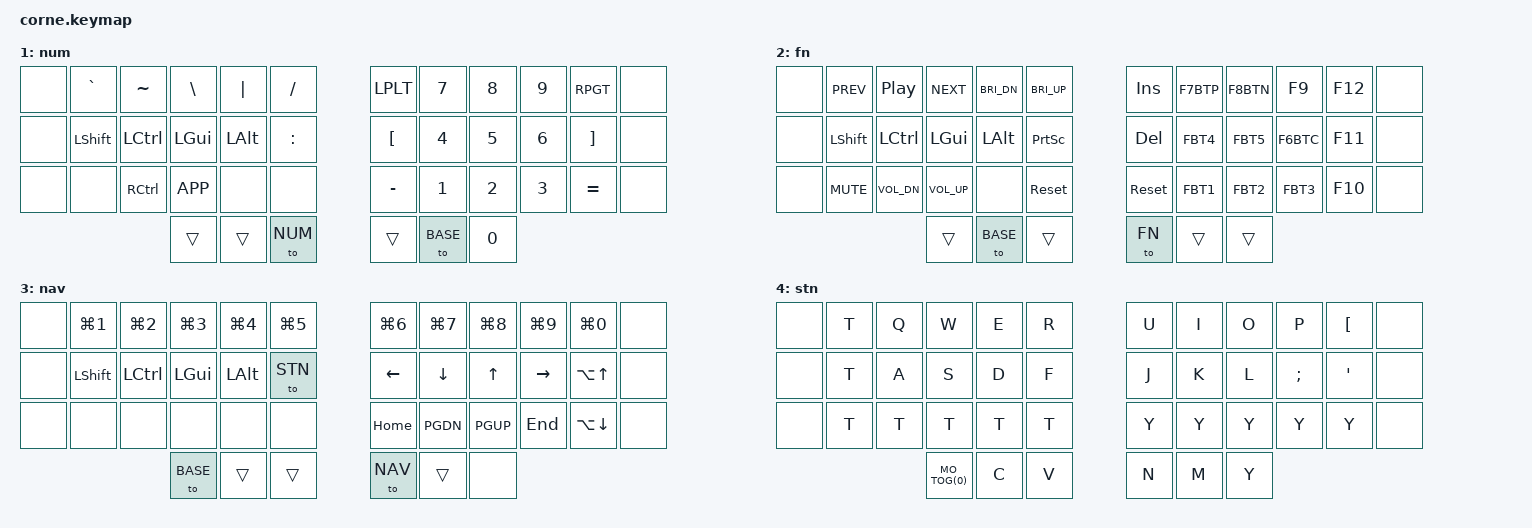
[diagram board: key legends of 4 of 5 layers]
#include <behaviors.dtsi>
#include <dt-bindings/zmk/keys.h>
#include <dt-bindings/zmk/bt.h>

/*────┬─────┬─────┬─────┬────L0:BASE──┬─────┬─────┬─────┬─────╮
│ ' " │ , < │ . > │ p P │ y Y │ │ f F │ g G │ c C │ r R │ l L │
│     │     │     │     │     │ │     │     │     │     │     │
├─────┼─────┼─────┼─────┼─────┤ ├─────┼─────┼─────┼─────┼─────┤
│ a A │ o O │ e E │ u U │ i I │ │ d D │ h H │ t T │ n N │ s S │
│ SHF │ CTL │ GUI │ ALT │     │ │     │ ALT │ GUI │ CTL │ SHF │
├─────┼─────┼─────┼─────┼─────┤ ├─────┼─────┼─────┼─────┼─────┤
│ ; : │ q Q │ j J │ k K │ x X │ │ b B │ m M │ w W │ v V │ z Z │
│     │     │     │     │     │ │     │     │     │     │     │
╰─────┴─────┼─────┼─────┼─────┤ ├─────┼─────┼─────┼─────┴─────╯
            │ ESC │BSPC │ TAB │ │ RET │SPACE│ / ? │
            │ NAV │ FN  │     │ │     │ NUM │     │
            ╰─────┴─────┴─────╯ ╰─────┴─────┴─────╯
╭─────┬─────┬─────┬─────┬────L1:NUM───┬─────┬─────┬─────┬─────╮
│  `  │  ~  │  \  │  |  │  /  │ │ ( < │ 7 & │ 8 * │  9  │ ) > │
│     │     │     │     │     │ │     │     │     │     │     │
├─────┼─────┼─────┼─────┼─────┤ ├─────┼─────┼─────┼─────┼─────┤
│ SHF │ CTL │ GUI │ ALT │  :  │ │ [ { │ 4 $ │ 5 % │ 6 ^ │ ] } │
│     │     │     │     │     │ │     │     │     │     │     │
├─────┼─────┼─────┼─────┼─────┤ ├─────┼─────┼─────┼─────┼─────┤
│ ... │RCTL │MENU │ ... │ ... │ │ - _ │ 1 ! │ 2 @ │ 3 # │ = + │
│     │     │     │     │     │ │     │     │     │     │     │
╰─────┴─────┼─────┼─────┼─────┤ ├─────┼─────┼─────┼─────┴─────╯
            │     │     │ NUM │ │     │BASE │  0  │
            │     │     │     │ │     │     │     │
            ╰─────┴─────┴─────╯ ╰─────┴─────┴─────╯
╭─────┬─────┬─────┬─────┬────L2:FN────┬─────┬─────┬─────┬─────╮
│PREV │ PP  │NEXT │BRIDN│BRIUP│ │ INS │F7 BP│F8 BN│F9   │ F12 │
│     │     │     │     │     │ │     │     │     │     │     │
├─────┼─────┼─────┼─────┼─────┤ ├─────┼─────┼─────┼─────┼─────┤
│ SHF │ CTL │ GUI │ ALT │PSCRN│ │ DEL │F4 B4│F5 B5│F6 BC│ F11 │
│     │     │     │     │     │ │     │     │     │     │     │
├─────┼─────┼─────┼─────┼─────┤ ├─────┼─────┼─────┼─────┼─────┤
│MUTE │ VDN │ VUP │ ... │RESET│ │RESET│F1 B1│F2 B2│F3 B3│ F10 │
│     │     │     │     │     │ │     │     │     │     │     │
╰─────┴─────┼─────┼─────┼─────┤ ├─────┼─────┼─────┼─────┴─────╯
            │     │BASE │     │ │ FN  │     │     │ ↑ GUI for
            │     │     │     │ │     │     │     │ B* (BT)
            ╰─────┴─────┴─────╯ ╰─────┴─────┴─────╯
╭─────┬─────┬─────┬─────┬────L3:NAV───┬─────┬─────┬─────┬─────╮
│LG(1)│LG(2)│LG(3)│LG(4)│LG(5)│ │LG(6)│LG(7)│LG(8)│LG(9)│LG(0)│
│     │     │     │     │     │ │     │     │     │     │     │
├─────┼─────┼─────┼─────┼─────┤ ├─────┼─────┼─────┼─────┼─────┤
│ SHF │ CTL │ GUI │ ALT │ STN │ │  ←  │  ↓  │  ↑  │  →  │LA(↑)│
│     │     │     │     │     │ │     │     │     │     │     │
├─────┼─────┼─────┼─────┼─────┤ ├─────┼─────┼─────┼─────┼─────┤
│ ... │ ... │ ... │ ... │ ... │ │HOME │ PG↓ │ PG↑ │ END │LA(↓)│
│     │     │     │     │     │ │     │     │     │     │     │
╰─────┴─────┼─────┼─────┼─────┤ ├─────┼─────┼─────┼─────┴─────╯
            │BASE │     │     │ │ NAV │LGTAB│     │
            │     │     │     │ │     │     │     │
            ╰─────┴─────┴─────╯ ╰─────┴─────┴─────╯
╭─────┬─────┬─────┬─────┬────L4:STN───┬─────┬─────┬─────┬─────╮
│  t  │  q  │  w  │  e  │  r  │ │  u  │  i  │  o  │  p  │  [  │
│     │     │     │     │     │ │     │     │     │     │     │
├─────┼─────┼─────┼─────┼─────┤ ├─────┼─────┼─────┼─────┼─────┤
│  t  │  a  │  s  │  d  │  f  │ │  j  │  k  │  l  │  ;  │  '  │
│     │     │     │     │     │ │     │     │     │     │     │
├─────┼─────┼─────┼─────┼─────┤ ├─────┼─────┼─────┼─────┼─────┤
│  t  │  t  │  t  │  t  │  t  │ │  y  │  y  │  y  │  y  │  y  │
│     │     │     │     │     │ │     │     │     │     │     │
╰─────┴─────┼─────┼─────┼─────┤ ├─────┼─────┼─────┼─────┴─────╯
            │ LV0 │  c  │  v  │ │  n  │  m  │  y  │
            │ LV0 │     │     │ │     │     │     │
            ╰─────┴─────┴─────╯ ╰─────┴─────┴────*/

#define NOP &none
#define __ &trans

#define LKEYS  1  2  3  4  5  13 14 15 16 17  25 26 27 28 29  36 37 38
#define RKEYS  6  7  8  9 10  18 19 20 21 22  30 31 32 33 34  39 40 41

#define BASE 0
#define NUM  1
#define FN   2
#define NAV  3
#define STN  4

#define NAV_ESC &ltb   NAV ESC
#define FN_BSPC &ltb   FN BSPC
#define NUM_SPACE &ltb NUM SPACE

// #define NAV_SPACE &ltb NAV SPACE
// #define NAV_BSPC  &ltb NAV BSPC
// #define NUM_TAB   &ltb NUM TAB
// #define FN_TAB    &ltb FN  TAB
// #define NUM_RET   &ltb NUM RET
// #define FN_BSPC   &ltb FN  BSPC

#define VMUTE &kp C_MUTE
#define VOLDN &kp C_VOL_DN
#define VOLUP &kp C_VOL_UP
#define BRIDN &kp C_BRI_DN
#define BRIUP &kp C_BRI_UP
#define PREV  &kp C_PREV
#define PP    &kp C_PP
#define NEXT  &kp C_NEXT

#define MO_TOG(layer) &mo_tog layer layer

#define HL(k1,k2,k3,k4) &hml LSHFT k1  &hml LCTRL k2  &hml LGUI k3  &hml LALT k4
#define HR(k1,k2,k3,k4) &hmr LALT k1  &hmr LGUI k2  &hmr LCTRL k3  &hmr LSHFT k4

/ {
  behaviors {
    mo_tog: behavior_mo_tog {
      compatible = "zmk,behavior-hold-tap";
      #binding-cells = <2>;
      flavor = "hold-preferred";
      tapping-term-ms = <200>;
      bindings = <&mo>, <&tog>;
    };
    ltb: layer_tap_balanced {
      compatible = "zmk,behavior-hold-tap";
      #binding-cells = <2>;
      flavor = "balanced";
      require-prior-idle-ms = <50>;
      tapping-term-ms = <170>;
      quick-tap-ms = <100>;
      bindings = <&mo>, <&kp>;
      display-name = "Layer-Tap";
      hold-trigger-on-release;
    };
    hml: home_row_mod_left {
      compatible = "zmk,behavior-hold-tap";
      #binding-cells = <2>;
      flavor = "balanced";
      require-prior-idle-ms = <50>;
      tapping-term-ms = <170>;
      quick-tap-ms = <100>;
      bindings = <&kp>, <&kp>;
      hold-trigger-key-positions = <RKEYS>;
      hold-trigger-on-release;
    };
    hmr: home_row_mod_right {
      compatible = "zmk,behavior-hold-tap";
      #binding-cells = <2>;
      flavor = "balanced";
      require-prior-idle-ms = <50>;
      tapping-term-ms = <170>;
      quick-tap-ms = <100>;
      bindings = <&kp>, <&kp>;
      hold-trigger-key-positions = <LKEYS>;
      hold-trigger-on-release;
    };
    LPLT: morph_LPAR_LT {
      compatible = "zmk,behavior-mod-morph";
      #binding-cells = <0>;
      bindings = <&kp LPAR>, <&kp LT>;
      mods = <(MOD_LSFT)>;
    };
    RPGT: morph_RPAR_GT {
      compatible = "zmk,behavior-mod-morph";
      #binding-cells = <0>;
      bindings = <&kp RPAR>, <&kp GT>;
      mods = <(MOD_LSFT)>;
    };
    FBT1: morph_F_BT_1 {
      compatible = "zmk,behavior-mod-morph";
      #binding-cells = <0>;
      bindings = <&kp F1>, <&bt BT_SEL 0>;
      mods = <(MOD_LGUI)>;
    };
    FBT2: morph_F_BT_2 {
      compatible = "zmk,behavior-mod-morph";
      #binding-cells = <0>;
      bindings = <&kp F2>, <&bt BT_SEL 1>;
      mods = <(MOD_LGUI)>;
    };
    FBT3: morph_F_BT_3 {
      compatible = "zmk,behavior-mod-morph";
      #binding-cells = <0>;
      bindings = <&kp F3>, <&bt BT_SEL 2>;
      mods = <(MOD_LGUI)>;
    };
    FBT4: morph_F_BT_4 {
      compatible = "zmk,behavior-mod-morph";
      #binding-cells = <0>;
      bindings = <&kp F4>, <&bt BT_SEL 3>;
      mods = <(MOD_LGUI)>;
    };
    FBT5: morph_F_BT_5 {
      compatible = "zmk,behavior-mod-morph";
      #binding-cells = <0>;
      bindings = <&kp F5>, <&bt BT_SEL 4>;
      mods = <(MOD_LGUI)>;
    };
    F6BTC: morph_F6_BTC {
      compatible = "zmk,behavior-mod-morph";
      #binding-cells = <0>;
      bindings = <&kp F6>, <&bt BT_CLR>;
      mods = <(MOD_LGUI)>;
    };
    F7BTP: morph_F7_BTP {
      compatible = "zmk,behavior-mod-morph";
      #binding-cells = <0>;
      bindings = <&kp F7>, <&bt BT_PRV>;
      mods = <(MOD_LGUI)>;
    };
    F8BTN: morph_F8_BTN {
      compatible = "zmk,behavior-mod-morph";
      #binding-cells = <0>;
      bindings = <&kp F8>, <&bt BT_NXT>;
      mods = <(MOD_LGUI)>;
    };
  };
  keymap { compatible = "zmk,keymap";

    BASE { display-name="base"; bindings = <
      NOP  &kp APOS   &kp COMMA  &kp DOT    &kp P      &kp Y        &kp F      &kp G      &kp C      &kp R      &kp L      NOP
      NOP  HL( A      ,   O      ,   E      ,   U   )  &kp I        &kp D      HR( H      ,   T      ,   N      ,   S   )  NOP
      NOP  &kp SEMI   &kp Q      &kp J      &kp K      &kp X        &kp B      &kp M      &kp W      &kp V      &kp Z      NOP
      /*                     */  NAV_ESC    FN_BSPC    &kp TAB      &kp RET    NUM_SPACE  &kp FSLH                       >; };

      NUM { display-name="num"; bindings = <
      NOP  &kp GRAVE  &kp TILDE  &kp BSLH   &kp PIPE   &kp FSLH     &LPLT      &kp N7     &kp N8     &kp N9     &RPGT      NOP
      NOP  &kp LSHFT  &kp LCTRL  &kp LGUI   &kp LALT   &kp COLON    &kp LBKT   &kp N4     &kp N5     &kp N6     &kp RBKT   NOP
      NOP  NOP        &kp RCTRL  &kp K_APP  NOP        NOP          &kp MINUS  &kp N1     &kp N2     &kp N3     &kp EQUAL  NOP
      /*                     */  &trans     &trans     &to NUM      &trans     &to BASE   &kp N0                         >; };

    FN { display-name="fn"; bindings = <
      NOP  PREV       PP         NEXT       BRIDN      BRIUP        &kp INS    &F7BTP     &F8BTN     &kp F9    &kp F12    NOP
      NOP  &kp LSHFT  &kp LCTRL  &kp LGUI   &kp LALT   &kp PSCRN    &kp DEL    &FBT4      &FBT5      &F6BTC    &kp F11    NOP
      NOP  VMUTE      VOLDN      VOLUP      NOP        &sys_reset   &sys_reset &FBT1      &FBT2      &FBT3     &kp F10    NOP
      /*                     */  &trans     &to BASE   &trans       &to FN     &trans     &trans                         >; };

    NAV { display-name="nav"; bindings = <
      NOP  &kp LG(N1) &kp LG(N2) &kp LG(N3) &kp LG(N4) &kp LG(N5)   &kp LG(N6) &kp LG(N7) &kp LG(N8) &kp LG(N9) &kp LG(N0) NOP
      NOP  &kp LSHFT  &kp LCTRL  &kp LGUI   &kp LALT   &to STN      &kp LEFT   &kp DOWN   &kp UP     &kp RIGHT  &kp LA(UP) NOP
      NOP  NOP        NOP        NOP        NOP        NOP          &kp HOME   &kp PGDN   &kp PGUP   &kp END  &kp LA(DOWN) NOP
      /*                     */  &to BASE   &trans     &trans       &to NAV    &trans      NOP                           >; };

    STN { display-name="stn"; bindings = <
      NOP  &kp T      &kp Q      &kp W      &kp E      &kp R        &kp U      &kp I      &kp O      &kp P      &kp LBKT   NOP
      NOP  &kp T      &kp A      &kp S      &kp D      &kp F        &kp J      &kp K      &kp L      &kp SEMI   &kp APOS   NOP
      NOP  &kp T      &kp T      &kp T      &kp T      &kp T        &kp Y      &kp Y      &kp Y      &kp Y      &kp Y      NOP
      /*                     */  MO_TOG(0)  &kp C      &kp V        &kp N      &kp M      &kp Y                          >; };
  };
};
/* vim: set list tw=128 cc=+0: */
